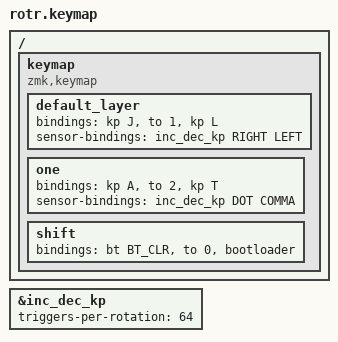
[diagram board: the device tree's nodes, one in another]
#include <behaviors.dtsi>
#include <dt-bindings/zmk/bt.h>
#include <dt-bindings/zmk/keys.h>

&inc_dec_kp {
    triggers-per-rotation = <64>;
};

/ {
    keymap {
        compatible = "zmk,keymap";
        default_layer {
            bindings = <&kp J &to 1 &kp L>;
            sensor-bindings = <&inc_dec_kp RIGHT LEFT>;
        };
        one {
            bindings = <&kp A &to 2 &kp T>;
            sensor-bindings = <&inc_dec_kp DOT COMMA>;
        };
        shift {
            bindings = <&bt BT_CLR &to 0 &bootloader>;
            // sensor-bindings = <&def_lshft>;
        };
    };
};
